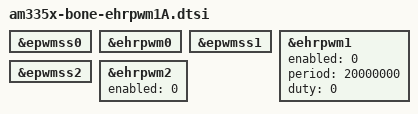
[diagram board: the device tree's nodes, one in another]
/*
 * Copyright (C) 2013 CircuitCo
 * Copyright (C) 2013 Texas Instruments
 *
 * This program is free software; you can redistribute it and/or modify
 * it under the terms of the GNU General Public License version 2 as
 * published by the Free Software Foundation.
 */

&epwmss0 {
	status = "okay";
};

&ehrpwm0 {
	status = "okay";
};

&epwmss1 {
	status = "okay";
};

&ehrpwm1 {
	enabled = <0>;
	period = <20000000>;
	duty   = <0>; 
	status = "okay";
};

&epwmss2 {
	status = "okay";
};

&ehrpwm2 {
	enabled = <0>;
	status = "okay";
};
